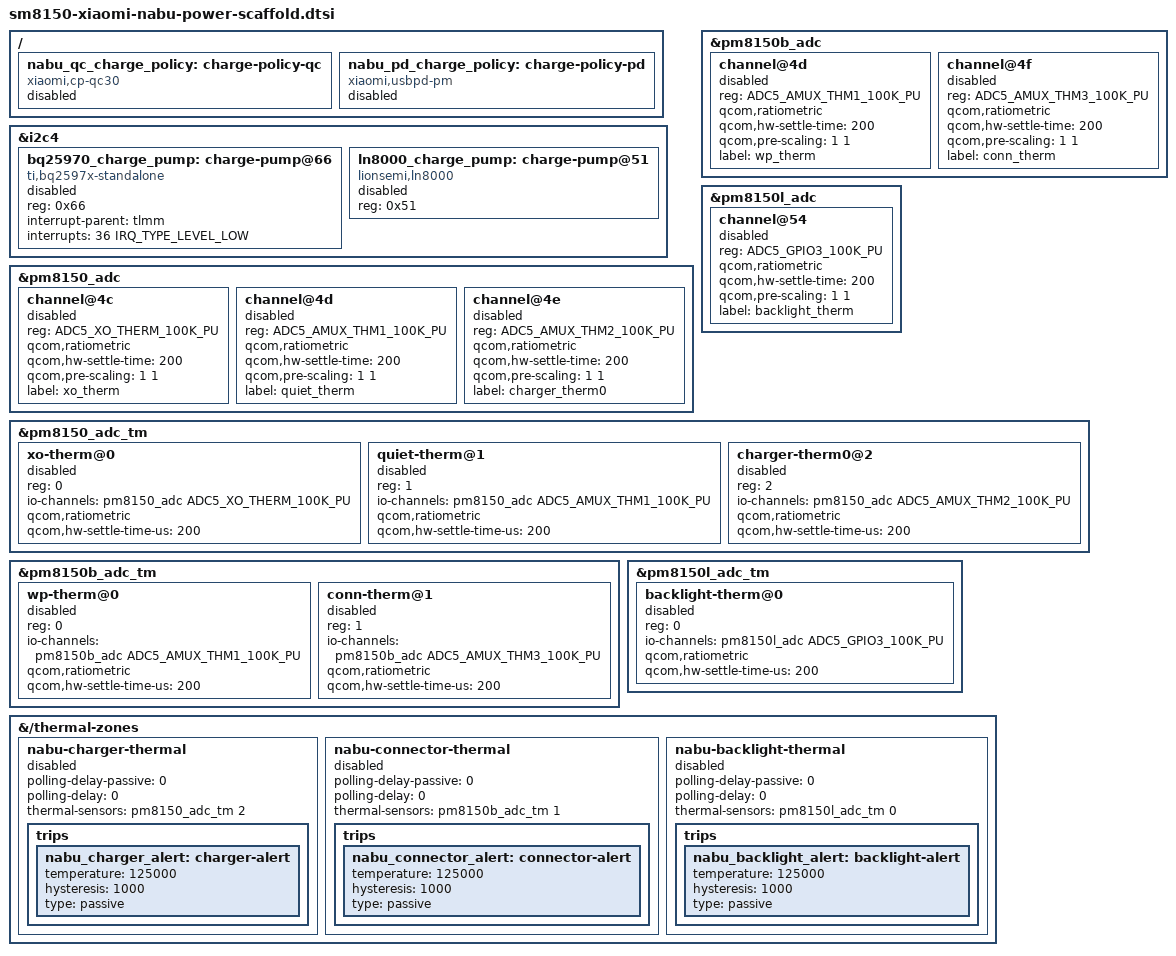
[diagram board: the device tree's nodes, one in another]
// SPDX-License-Identifier: BSD-3-Clause
/*
 * Copyright (c) 2026 Nabu Linux contributors
 *
 * Inactive board description for the optional high-power charging path and
 * board thermistors found in the downstream Xiaomi kernel.  Every node in
 * this file is disabled until the hardware variant and Linux driver
 * support have been verified on a physical device.
 */

&i2c4 {
	bq25970_charge_pump: charge-pump@66 {
		compatible = "ti,bq2597x-standalone";
		reg = <0x66>;
		interrupt-parent = <&tlmm>;
		interrupts = <36 IRQ_TYPE_LEVEL_LOW>;
		status = "disabled";
	};

	ln8000_charge_pump: charge-pump@51 {
		compatible = "lionsemi,ln8000";
		reg = <0x51>;
		status = "disabled";
	};
};

/* Platform policy drivers are not part of a memory-mapped bus. */
/ {
	nabu_qc_charge_policy: charge-policy-qc {
		compatible = "xiaomi,cp-qc30";
		status = "disabled";
	};

	nabu_pd_charge_policy: charge-policy-pd {
		compatible = "xiaomi,usbpd-pm";
		status = "disabled";
	};
};

&pm8150_adc {
	channel@4c {
		reg = <ADC5_XO_THERM_100K_PU>;
		qcom,ratiometric;
		qcom,hw-settle-time = <200>;
		qcom,pre-scaling = <1 1>;
		label = "xo_therm";
		status = "disabled";
	};

	channel@4d {
		reg = <ADC5_AMUX_THM1_100K_PU>;
		qcom,ratiometric;
		qcom,hw-settle-time = <200>;
		qcom,pre-scaling = <1 1>;
		label = "quiet_therm";
		status = "disabled";
	};

	channel@4e {
		reg = <ADC5_AMUX_THM2_100K_PU>;
		qcom,ratiometric;
		qcom,hw-settle-time = <200>;
		qcom,pre-scaling = <1 1>;
		label = "charger_therm0";
		status = "disabled";
	};
};

&pm8150b_adc {
	channel@4d {
		reg = <ADC5_AMUX_THM1_100K_PU>;
		qcom,ratiometric;
		qcom,hw-settle-time = <200>;
		qcom,pre-scaling = <1 1>;
		label = "wp_therm";
		status = "disabled";
	};

	channel@4f {
		reg = <ADC5_AMUX_THM3_100K_PU>;
		qcom,ratiometric;
		qcom,hw-settle-time = <200>;
		qcom,pre-scaling = <1 1>;
		label = "conn_therm";
		status = "disabled";
	};
};

&pm8150l_adc {
	channel@54 {
		reg = <ADC5_GPIO3_100K_PU>;
		qcom,ratiometric;
		qcom,hw-settle-time = <200>;
		qcom,pre-scaling = <1 1>;
		label = "backlight_therm";
		status = "disabled";
	};
};

&pm8150_adc_tm {
	xo-therm@0 {
		reg = <0>;
		io-channels = <&pm8150_adc ADC5_XO_THERM_100K_PU>;
		qcom,ratiometric;
		qcom,hw-settle-time-us = <200>;
		status = "disabled";
	};

	quiet-therm@1 {
		reg = <1>;
		io-channels = <&pm8150_adc ADC5_AMUX_THM1_100K_PU>;
		qcom,ratiometric;
		qcom,hw-settle-time-us = <200>;
		status = "disabled";
	};

	charger-therm0@2 {
		reg = <2>;
		io-channels = <&pm8150_adc ADC5_AMUX_THM2_100K_PU>;
		qcom,ratiometric;
		qcom,hw-settle-time-us = <200>;
		status = "disabled";
	};
};

&pm8150b_adc_tm {
	wp-therm@0 {
		reg = <0>;
		io-channels = <&pm8150b_adc ADC5_AMUX_THM1_100K_PU>;
		qcom,ratiometric;
		qcom,hw-settle-time-us = <200>;
		status = "disabled";
	};

	conn-therm@1 {
		reg = <1>;
		io-channels = <&pm8150b_adc ADC5_AMUX_THM3_100K_PU>;
		qcom,ratiometric;
		qcom,hw-settle-time-us = <200>;
		status = "disabled";
	};
};

&pm8150l_adc_tm {
	backlight-therm@0 {
		reg = <0>;
		io-channels = <&pm8150l_adc ADC5_GPIO3_100K_PU>;
		qcom,ratiometric;
		qcom,hw-settle-time-us = <200>;
		status = "disabled";
	};
};

&{/thermal-zones} {
	nabu-charger-thermal {
		polling-delay-passive = <0>;
		polling-delay = <0>;
		thermal-sensors = <&pm8150_adc_tm 2>;
		status = "disabled";

		trips {
			nabu_charger_alert: charger-alert {
				temperature = <125000>;
				hysteresis = <1000>;
				type = "passive";
			};
		};
	};

	nabu-connector-thermal {
		polling-delay-passive = <0>;
		polling-delay = <0>;
		thermal-sensors = <&pm8150b_adc_tm 1>;
		status = "disabled";

		trips {
			nabu_connector_alert: connector-alert {
				temperature = <125000>;
				hysteresis = <1000>;
				type = "passive";
			};
		};
	};

	nabu-backlight-thermal {
		polling-delay-passive = <0>;
		polling-delay = <0>;
		thermal-sensors = <&pm8150l_adc_tm 0>;
		status = "disabled";

		trips {
			nabu_backlight_alert: backlight-alert {
				temperature = <125000>;
				hysteresis = <1000>;
				type = "passive";
			};
		};
	};
};
